# MCXA133 register map
Vendor: nxp.com; File version: 1.0
CPU: CM33 r2p0, little endian, no MPU, no FPU, VTOR, 3 interrupt priority bits
Registers are 32-bit, read-write, reset 0x0 unless marked. A register's access mark holds for its fields unless they carry their own. Offsets are from the block's base; [hi:lo] are bit positions; {n}, {i} and the like mark numbered series.

## WWDT0 — WWDT
Base 0x4000C000
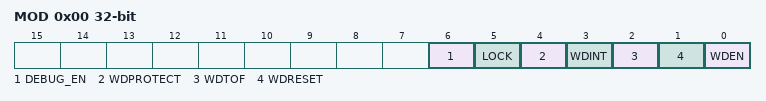
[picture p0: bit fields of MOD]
0x00 MOD — Mode
  [6] DEBUG_EN — Debug Enable
    0=DISABLE (Disabled); 1=ENABLE (Enabled)
  [5] LOCK
    0=NO_LOCK; 1=LOCK
  [4] WDPROTECT — Watchdog Update Mode
    0=FLEXIBLE; 1=THRESHOLD
  [3] WDINT write-1-clears — Warning Interrupt Flag
    0=NO_FLAG; 1=FLAG
  [2] WDTOF — Watchdog Timeout Flag
    0=CLEAR (Watchdog event has not occurred.); 1=RESET (Watchdog event has occurred (causes a chip reset if WDRESET = 1).)
  [1] WDRESET — Watchdog Reset Enable
    0=INTERRUPT; 1=RESET
  [0] WDEN — Watchdog Enable
    0=STOP (Timer stopped); 1=RUN (Timer running)
0x04 TC reset 0xFF — Timer Constant
  [23:0] COUNT — Watchdog Timeout Value
0x08 FEED wo reset not defined — Feed Sequence
  [7:0] FEED — Feed Value
0x0C TV ro reset 0xFF — Timer Value
  [23:0] COUNT — Counter Timer Value
0x14 WARNINT — Warning Interrupt Compare Value
  [9:0] WARNINT — Watchdog Warning Interrupt Compare Value
0x18 WINDOW reset 0xFFFFFF — Window Compare Value
  [23:0] WINDOW — Watchdog Window Value

## DMA0 — DMA MP
Base 0x40080000
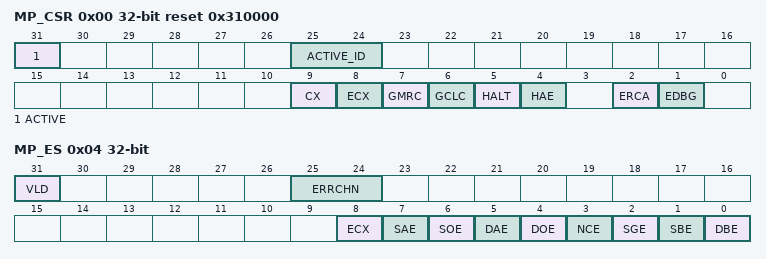
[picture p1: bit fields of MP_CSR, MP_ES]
0x00 MP_CSR reset 0x310000 — Management Page Control
  [31] ACTIVE ro — DMA Active Status
    0=IDLE (eDMA is idle); 1=EXECUTION (eDMA is executing a channel)
  [25:24] ACTIVE_ID ro — Active Channel ID
  [9] CX — Cancel Transfer
    0=NORMAL_OPERATION; 1=DATA_TRANSFER_CANCEL (Cancel the remaining data transfer)
  [8] ECX — Cancel Transfer With Error
    0=NORMAL_OPERATION; 1=CANCEL (Cancel the remaining data transfer)
  [7] GMRC — Global Master ID Replication Control
    0=DISABLE (Master ID replication disabled for all channels); 1=AVAILABLE (Master ID replication available and controlled by each channel's CHn_SBR[EMI] setting)
  [6] GCLC — Global Channel Linking Control
    0=DISABLE (Channel linking disabled for all channels); 1=AVAILABLE (Channel linking available and controlled by each channel's link settings)
  [5] HALT — Halt DMA Operations
    0=NORMAL_OPERATION; 1=STALL (Stall the start of any new channels)
  [4] HAE — Halt After Error
    0=NORMAL_OPERATION; 1=HALT (Any error causes the HALT field to be set to 1)
  [2] ERCA — Enable Round Robin Channel Arbitration
    0=DISABLE (Round-robin channel arbitration disabled); 1=ENABLE (Round-robin channel arbitration enabled)
  [1] EDBG — Enable Debug
    0=DISABLE (Debug mode disabled); 1=ENABLE (Debug mode is enabled.)
0x04 MP_ES ro — Management Page Error Status
  [31] VLD — Valid
    0=NO_FIELD_SET_ONE (No CHn_ES[ERR] fields are set to 1); 1=ATLEAST_ONE_FIELD (At least one CHn_ES[ERR] field is set to 1, indicating a valid error exists that software has not cleared)
  [25:24] ERRCHN — Error Channel Number or Canceled Channel Number
  [8] ECX — Transfer Canceled
    0=NO_CANCELED_TRANSFERS; 1=CANCELED_TRANSFER (Last recorded entry was a canceled transfer by the error cancel transfer input)
  [7] SAE — Source Address Error
    0=NO_ERROR (No source address configuration error); 1=CONFIGURATION_ERROR (Last recorded error was a configuration error detected in the TCDn_SADDR field)
  [6] SOE — Source Offset Error
    0=NO_ERROR (No source offset configuration error); 1=CONFIGURATION_ERROR (Last recorded error was a configuration error detected in the TCDn_SOFF field)
  [5] DAE — Destination Address Error
    0=NO_ERROR (No destination address configuration error); 1=CONFIGURATION_ERROR (Last recorded error was a configuration error detected in the TCDn_DADDR field)
  [4] DOE — Destination Offset Error
    0=NO_ERROR (No destination offset configuration error); 1=CONFIGURATION_ERROR (Last recorded error was a configuration error detected in the TCDn_DOFF field)
  [3] NCE — NBYTES/CITER Configuration Error
    0=NO_ERROR (No NBYTES/CITER configuration error); 1=CONFIGURATION_ERROR (The last recorded error was NBYTES equal to zero or a CITER not equal to BITER error)
  [2] SGE — Scatter/Gather Configuration Error
    0=NO_ERROR (No scatter/gather configuration error); 1=CONFIGURATION_ERROR (Last recorded error was a configuration error detected in the TCDn_DLAST_SGA field)
  [1] SBE — Source Bus Error
    0=NO_ERROR (No source bus error); 1=BUS_ERROR (Last recorded error was a bus error on a source read)
  [0] DBE — Destination Bus Error
    0=NO_ERROR (No destination bus error); 1=BUS_ERROR (Last recorded error was a bus error on a destination write)
0x08 MP_INT ro — Management Page Interrupt Request Status
  [3:0] INT — Interrupt Request Status
0x0C MP_HRS ro — Management Page Hardware Request Status
  [31:0] HRS — Hardware Request Status
{0x100+4i} CH_GRPRI[{i}] (i=0..3) — Channel Arbitration Group
  [4:0] GRPRI — Arbitration Group For Channel n
